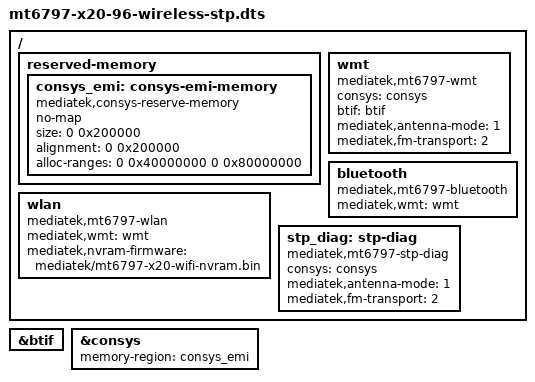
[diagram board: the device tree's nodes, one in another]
// SPDX-License-Identifier: GPL-2.0-only
/* Opt-in X20-96 DTB for the bounded MT6797 BTIF/STP/WMT experiment. */
/dts-v1/;

#include "mt6797-x20-96-headless.dts"

/ {
	/*
	 * Vendor MT6797 reserves 2 MiB aligned to 2 MiB for ConSys.  The Wi-Fi
	 * divided firmware uses the first 512 KiB; the remaining offsets are
	 * shared with ConSys diagnostics/GPS. The ConSys power owner programs its
	 * remap/MPU before MCU reset release, using the matching BL31 service.
	 */
	reserved-memory {
		#address-cells = <2>;
		#size-cells = <2>;
		ranges;

		consys_emi: consys-emi-memory {
			compatible = "mediatek,consys-reserve-memory";
			no-map;
			size = <0 0x200000>;
			alignment = <0 0x200000>;
			alloc-ranges = <0 0x40000000 0 0x80000000>;
		};
	};

	wmt: wmt {
		compatible = "mediatek,mt6797-wmt";
		consys = <&consys>;
		btif = <&btif>;
		mediatek,antenna-mode = /bits/ 8 <1>;
		mediatek,fm-transport = /bits/ 8 <2>;
		status = "okay";
	};

	wlan {
		compatible = "mediatek,mt6797-wlan";
		mediatek,wmt = <&wmt>;
		mediatek,nvram-firmware = "mediatek/mt6797-x20-wifi-nvram.bin";
		status = "okay";
	};

	bluetooth {
		compatible = "mediatek,mt6797-bluetooth";
		mediatek,wmt = <&wmt>;
		status = "okay";
	};

	stp_diag: stp-diag {
		compatible = "mediatek,mt6797-stp-diag";
		consys = <&consys>;
		/* X20 BSP WMT_SOC.cfg: antenna mode 1, external 26 MHz TCXO. */
		mediatek,antenna-mode = /bits/ 8 <1>;
		mediatek,fm-transport = /bits/ 8 <2>;
		status = "okay";
	};
};

&btif {
	status = "okay";
};

&consys {
	memory-region = <&consys_emi>;
};
